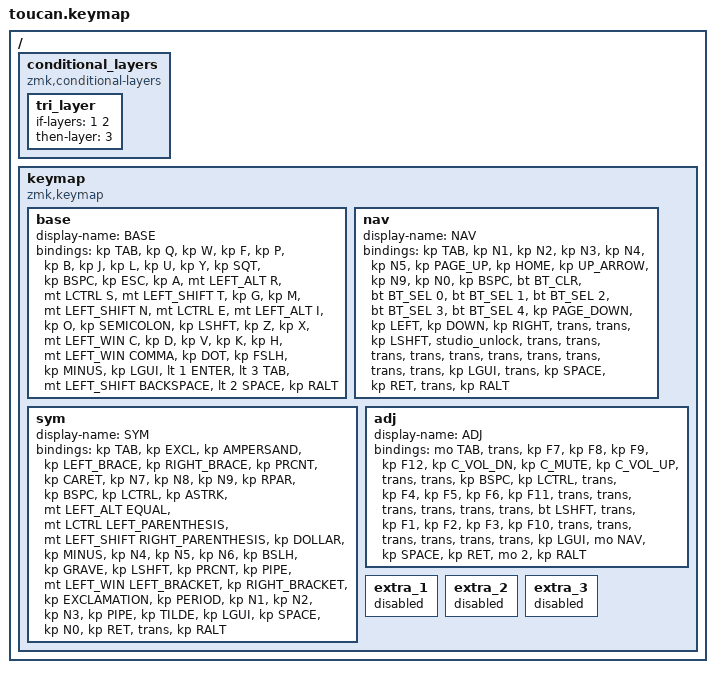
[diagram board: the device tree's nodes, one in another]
#include <behaviors.dtsi>
#include <dt-bindings/zmk/bt.h>
#include <dt-bindings/zmk/keys.h>
#include <dt-bindings/zmk/behaviors.h>
#include <dt-bindings/zmk/outputs.h>

#define BASE 0
#define NAV  1
#define SYM  2
#define ADJ  3

/ {
    conditional_layers {
        compatible = "zmk,conditional-layers";

        tri_layer {
            if-layers = <1 2>;
            then-layer = <3>;
        };
    };

    keymap {
        compatible = "zmk,keymap";
        base {
            display-name = "BASE";
            bindings = <
&kp TAB  &kp Q  &kp W  &kp F  &kp P  &kp B  &kp J  &kp L  &kp U  &kp Y  &kp SQT  &kp BSPC  &kp ESC  &kp A  &mt LEFT_ALT R  &mt LCTRL S  &mt LEFT_SHIFT T  &kp G  &kp M  &mt LEFT_SHIFT N  &mt LCTRL E  &mt LEFT_ALT I  &kp O  &kp SEMICOLON  &kp LSHFT  &kp Z  &kp X  &mt LEFT_WIN C  &kp D  &kp V  &kp K  &kp H  &mt LEFT_WIN COMMA  &kp DOT  &kp FSLH  &kp MINUS  &kp LGUI  &lt 1 ENTER  &lt 3 TAB  &mt LEFT_SHIFT BACKSPACE  &lt 2 SPACE  &kp RALT
            >;
        };

        nav {
            display-name = "NAV";
            bindings = <
&kp TAB  &kp N1  &kp N2  &kp N3  &kp N4  &kp N5  &kp PAGE_UP  &kp HOME  &kp UP_ARROW  &kp N9  &kp N0  &kp BSPC  &bt BT_CLR  &bt BT_SEL 0  &bt BT_SEL 1  &bt BT_SEL 2  &bt BT_SEL 3  &bt BT_SEL 4  &kp PAGE_DOWN  &kp LEFT  &kp DOWN  &kp RIGHT  &trans  &trans  &kp LSHFT  &studio_unlock  &trans  &trans  &trans  &trans  &trans  &trans  &trans  &trans  &trans  &trans  &kp LGUI  &trans  &kp SPACE  &kp RET  &trans  &kp RALT
            >;
        };

        sym {
            display-name = "SYM";
            bindings = <
&kp TAB  &kp EXCL  &kp AMPERSAND  &kp LEFT_BRACE  &kp RIGHT_BRACE  &kp PRCNT  &kp CARET  &kp N7  &kp N8  &kp N9  &kp RPAR  &kp BSPC  &kp LCTRL  &kp ASTRK  &mt LEFT_ALT EQUAL  &mt LCTRL LEFT_PARENTHESIS  &mt LEFT_SHIFT RIGHT_PARENTHESIS  &kp DOLLAR  &kp MINUS  &kp N4  &kp N5  &kp N6  &kp BSLH  &kp GRAVE  &kp LSHFT  &kp PRCNT  &kp PIPE  &mt LEFT_WIN LEFT_BRACKET  &kp RIGHT_BRACKET  &kp EXCLAMATION  &kp PERIOD  &kp N1  &kp N2  &kp N3  &kp PIPE  &kp TILDE  &kp LGUI  &kp SPACE  &kp N0  &kp RET  &trans  &kp RALT
            >;
        };

        adj {
            display-name = "ADJ";
            bindings = <
&mo TAB  &trans  &kp F7  &kp F8  &kp F9  &kp F12  &kp C_VOL_DN  &kp C_MUTE  &kp C_VOL_UP  &trans  &trans  &kp BSPC  &kp LCTRL  &trans  &kp F4  &kp F5  &kp F6  &kp F11  &trans  &trans  &trans  &trans  &trans  &trans  &bt LSHFT  &trans  &kp F1  &kp F2  &kp F3  &kp F10  &trans  &trans  &trans  &trans  &trans  &trans  &kp LGUI  &mo NAV  &kp SPACE  &kp RET  &mo 2  &kp RALT
            >;
        };

        extra_1 { status = "reserved"; };

        extra_2 { status = "reserved"; };

        extra_3 { status = "reserved"; };
    };
};
